# CMSDK_ARMv8MML_DP register map
Vendor: ARM Ltd.; Series: ARMv8-M Mainline; File version: 1.0
CPU: ARMV8MML r0p0, little endian, MPU, FPU, double-precision FPU, 3 interrupt priority bits, 4 SAU regions
Registers are 32-bit, read-write, reset 0x0 unless marked. A register's access mark holds for its fields unless they carry their own. Offsets are from the block's base; [hi:lo] are bit positions; {n}, {i} and the like mark numbered series; 'fields as' and 'values as' point back to an identical list.

## DUALTIMER
Base 0x40002000
0x00 TIMER1LOAD
0x04 TIMER1VALUE ro reset 0xFFFFFFFF
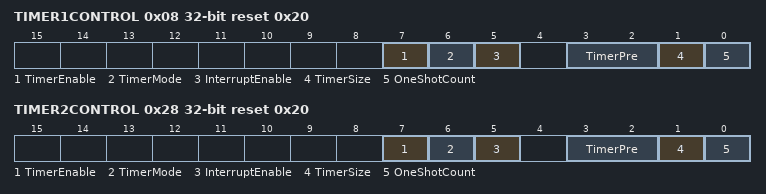
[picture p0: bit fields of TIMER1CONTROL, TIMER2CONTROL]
0x08 TIMER1CONTROL reset 0x20
  [7] TimerEnable — Timer Enable Enable bit.
    0=Disable (Timer is disabled.); 1=Enable (Timer is enabled.)
  [6] TimerMode — Timer Mode bit.
    0=Free-Running timer mode; 1=Periodic timer mode
  [5] InterruptEnable — Interrupt Enable bit.
    0=Disable (Interrupt is disabled.); 1=Enable (Interrupt is enabled.)
  [3:2] TimerPre — Timer prescale bits.
    0=divided by 1 (clock is divided by 1); 1=divided by 16 (clock is divided by 16); 2=divided by 256 (clock is divided by 256)
  [1] TimerSize — Selects 16-bit or 32- bit counter operation.
    0=16-bit counter mode; 1=32-bit counter mode
  [0] OneShotCount — Selects one-shot or wrapping counter mode.
    0=Wrapping counter mode; 1=One-shot counter mode
0x0C TIMER1INTCLR wo — Timer 1 Interrupt Clear Register
  [0] INT write-1-clears — Interrupt
0x10 TIMER1RIS ro — Timer 1 Raw Interrupt Status Register
  [0] RIS — Raw Timer Interrupt
0x14 TIMER1MIS ro — Timer 1 Mask Interrupt Status Register
  [0] MIS — Masked Timer Interrupt
0x18 TIMER1BGLOAD — Timer 1 Background Load Register
0x20 TIMER2LOAD
0x24 TIMER2VALUE ro reset 0xFFFFFFFF
0x28 TIMER2CONTROL reset 0x20
  fields as TIMER1CONTROL
0x2C TIMER2INTCLR wo — Timer 2 Interrupt Clear Register
  [0] INT write-1-clears — Interrupt
0x30 TIMER2RIS ro — Timer 2 Raw Interrupt Status Register
  [0] RIS — Raw Timer Interrupt
0x34 TIMER2MIS ro — Timer 2 Mask Interrupt Status Register
  [0] MIS — Masked Timer Interrupt
0x38 TIMER2BGLOAD — Timer 2 Background Load Register

## UART0
Base 0x40004000
Same registers: UART1 0x40005000, UART2 0x40006000, UART3 0x40007000, UART4 0x40009000
0x00 DATA 8-bit — Recieve and Transmit Data Value
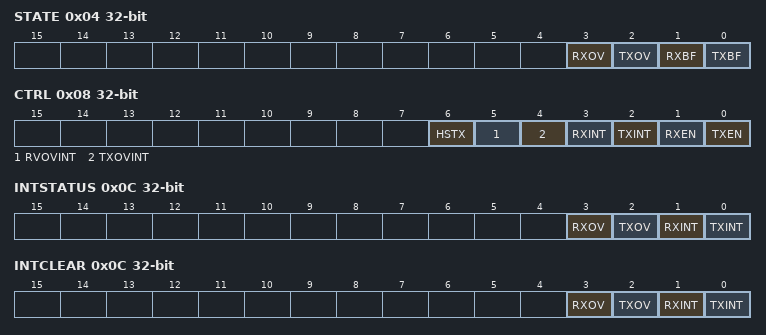
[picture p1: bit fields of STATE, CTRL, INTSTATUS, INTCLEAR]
0x04 STATE — UART Status Register
  [3] RXOV write-1-clears — RX Buffer Overun (write 1 to clear)
  [2] TXOV write-1-clears — TX Buffer Overun (write 1 to clear)
  [1] RXBF ro — RX Buffer Full
  [0] TXBF ro — TX Buffer Full
0x08 CTRL — UART Control Register
  [all] fields
    0=Disabled; 1=Enabled
  [6] HSTX — High Speed Test Mode for TX only
  [5] RVOVINT — RX Overrun Interrupt Enable
  [4] TXOVINT — TX Overrun Interrupt Enable
  [3] RXINT — RX Interrupt Enable
  [2] TXINT — TX Interrupt Enable
  [1] RXEN — RX Enable
  [0] TXEN — TX Enable
0x0C INTSTATUS ro — UART Interrupt Status Register
  [3] RXOV — RX Overrun Interrupt
  [2] TXOV — TX Overrun Interrupt
  [1] RXINT — RX Interrupt
  [0] TXINT — TX Interrupt
0x0C INTCLEAR wo (alternate view of INTSTATUS) — UART Interrupt CLEAR Register
  [3] RXOV write-1-clears — RX Overrun Interrupt
  [2] TXOV write-1-clears — TX Overrun Interrupt
  [1] RXINT write-1-clears — RX Interrupt
  [0] TXINT write-1-clears — TX Interrupt
0x10 BAUDDIV — Baudrate Divider

## GPIO0 — general-purpose I/O
Base 0x40010000
Same registers: GPIO1 0x40011000
0x00 DATA
0x04 DATAOUT — Data Output Register
0x10 OUTENSET — Ouptut enable set Register
0x14 OUTENCLR — Ouptut enable clear Register
0x18 ALTFUNCSET — Alternate function set Register
0x1C ALTFUNCCLR — Alternate function clear Register
0x20 INTENSET — Interrupt enable set Register
0x24 INTENCLR — Interrupt enable clear Register
0x28 INTTYPESET — Interrupt type set Register
0x2C INTTYPECLR — Interrupt type clear Register
0x30 INTPOLSET — Polarity-level, edge interrupt configuration set Register
0x34 INTPOLCLR — Polarity-level, edge interrupt configuration clear Register
0x38 INTSTATUS ro — Interrupt Status Register
0x38 INTCLEAR wo write-1-clears (alternate view of INTSTATUS) — Interrupt CLEAR Register

## SPI
Base 0x40027000
0x00 SPSTAT 16-bit — SPI Status
0x02 SPDAT 16-bit — SPI Data
0x04 SPCLK 16-bit — SPI Clock Configuration
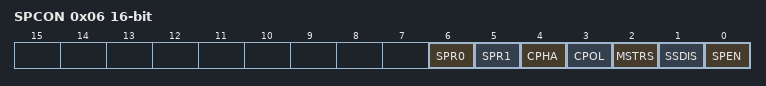
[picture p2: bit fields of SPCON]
0x06 SPCON 16-bit — SPI Configuration
  [6] SPR0, [5] SPR1, [4] CPHA, [3] CPOL, [2] MSTRS, [1] SSDIS, [0] SPEN

## WDT — Watchdog Timer
Base 0x40008000
0x00 WDOGLOAD reset 0xFFFFFFFF — Watchdog Load Register
0x04 WDOGVALUE ro reset 0xFFFFFFFF — Watchdog Value Register
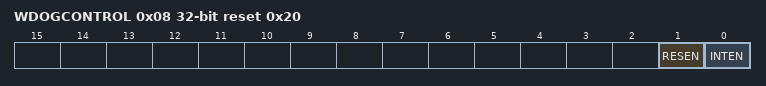
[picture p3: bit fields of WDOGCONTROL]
0x08 WDOGCONTROL reset 0x20 — Watchdog Control Register
  [1] RESEN — Enable watchdog reset output
    0=Disable Watchdog reset; 1=ENable Watchdog reset
  [0] INTEN — Enable the interrupt event
    0=Disable Watchdog interrupt; 1=ENable Watchdog interrupt
0x0C WDOGINTCLR wo — Watchdog Interrupt Clear Register
  [0] INT write-1-clears — Interrupt
0x10 WDOGRIS ro — Watchdog Raw Interrupt Status Register
  [0] RIS — Raw watchdog Interrupt
0x14 WDOGMIS ro — Watchdog Mask Interrupt Status Register
  [0] MIS — Masked Watchdog Interrupt
0xC00 WDOGLOCK — Watchdog Lock Register

## FPGAIO — FPGA System Control I/O
Base 0x40028000
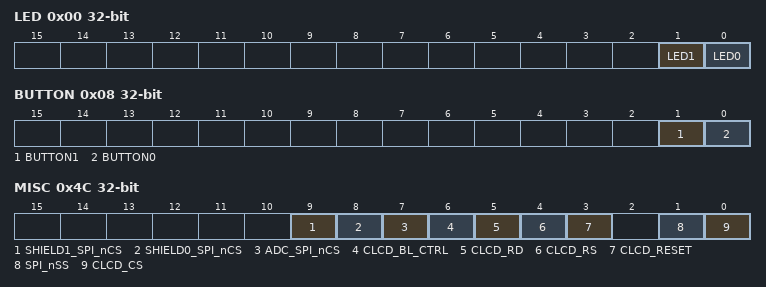
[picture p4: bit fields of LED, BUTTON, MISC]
0x00 LED — LED Connections
  [1] LED1
    0=Off (LED is off); 1=On (LED is on)
  [0] LED0
    0=Off (LED is off); 1=On (LED is on)
0x08 BUTTON — Button Connections
  [1] BUTTON1
    0=Off (BUTTON is off); 1=On (BUTTON is on)
  [0] BUTTON0
    0=Off (BUTTON is off); 1=On (BUTTON is on)
0x10 CLK1HZ ro — 1Hz Up Counter
0x14 CLK100HZ ro — 100Hz Up Counter
0x18 COUNTER — Cycle up counter
0x1C PRESCALER — Reload value for prescaler counter
0x20 PSCNTR — Prescale Counter
0x4C MISC — Misc. Control
  [9] SHIELD1_SPI_nCS, [8] SHIELD0_SPI_nCS, [7] ADC_SPI_nCS, [6] CLCD_BL_CTRL, [5] CLCD_RD, [4] CLCD_RS, [3] CLCD_RESET, [1] SPI_nSS, [0] CLCD_CS

## SCC — Serial Communication Controller
Base 0x4002F000
0x00 CFG_REG0
  [0] REMAP — 1 = REMAP Block RAM to ZBT
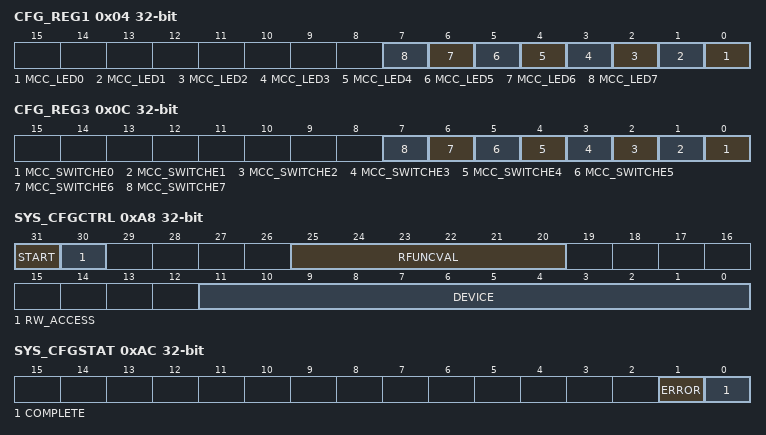
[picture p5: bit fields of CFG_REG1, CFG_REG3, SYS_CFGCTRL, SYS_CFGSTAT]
0x04 CFG_REG1
  [all] fields
    0=Off (LED is off); 1=On (LED is on)
  [n] MCC_LED{n} (n=0..7) — MCC LEDs: 0 = OFF 1 = ON
0x08 CFG_REG2 ro
0x0C CFG_REG3 ro
  [all] fields
    0=Off (Switch is off); 1=On (Switch is on)
  [n] MCC_SWITCHE{n} (n=0..7) — MCC SWITCHES: 0 = OFF 1 = ON
0x10 CFG_REG4 ro
  [3:0] BRDREV — Board Revision
0x14 CFG_REG5
  [5] DEBUG — Debug: 0 = Serial Wire Debug 1 = JTAG
0x18 CFG_REG6 ro
0x1C CFG_REG7 ro
0xA0 SYS_CFGDATA_RTN
0xA4 SYS_CFGDATA_OUT
0xA8 SYS_CFGCTRL
  [31] START — Start: generates interrupt on write to this bit
  [30] RW_ACCESS — Read/Write Access
  [25:20] RFUNCVAL — Function Value
  [11:0] DEVICE — Device (value of 0/1/2 for supported clocks
0xAC SYS_CFGSTAT
  [1] ERROR — Error Flag
  [0] COMPLETE — Complete Flag
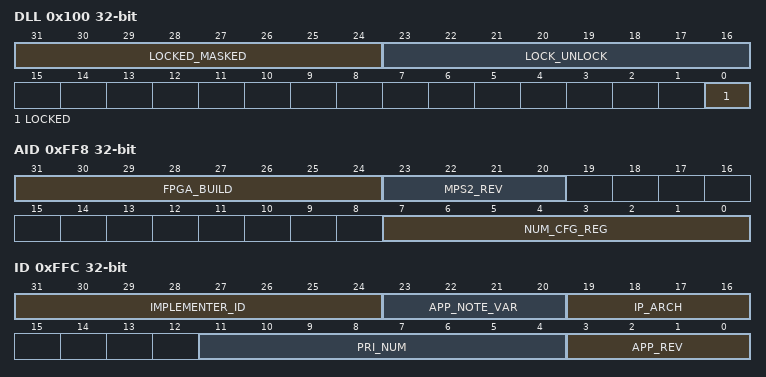
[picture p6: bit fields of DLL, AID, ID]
0x100 DLL — DLL Lock Register
  [31:24] LOCKED_MASKED — Error Flag
  [23:16] LOCK_UNLOCK — Complete Flag
  [0] LOCKED — Complete Flag
0xFF8 AID ro
  [31:24] FPGA_BUILD — FPGA Build Number
  [23:20] MPS2_REV — V2M-MPS2 target Board Revision (A=0,B=1,C=2)
  [7:0] NUM_CFG_REG — Number of SCC configuration register
0xFFC ID ro
  [31:24] IMPLEMENTER_ID — Implementer ID: 0x41 = ARM
  [23:20] APP_NOTE_VAR — Application note IP variant number
  [19:16] IP_ARCH — IP Architecture: 0x4 = AHB
  [11:4] PRI_NUM — Primary Part Number: 383 = AN383
  [3:0] APP_REV — Application note IP revision number
